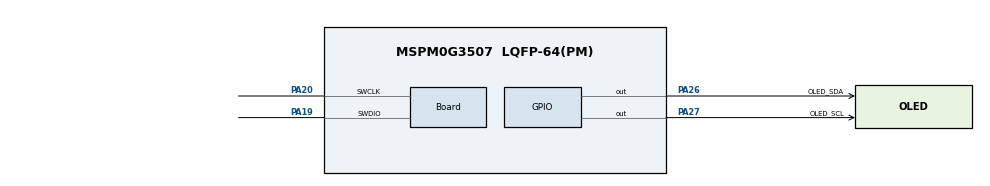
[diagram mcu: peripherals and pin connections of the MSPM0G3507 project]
/**
 * LP-MSPM0G3507 eight-channel line sensor test configuration.
 * I2C1: SCL=PA15, SDA=PA16. OLED software I2C: SCL=PA27, SDA=PA26.
 * @cliArgs --device "MSPM0G3507" --package "LQFP-64(PM)" --product "mspm0_sdk@2.10.00.04"
 */
const Board         = scripting.addModule("/ti/driverlib/Board");
const GPIO          = scripting.addModule("/ti/driverlib/GPIO", {}, false);
const GPIO1         = GPIO.addInstance();
const I2C           = scripting.addModule("/ti/driverlib/I2C", {}, false);
const I2C1          = I2C.addInstance();
const SYSCTL        = scripting.addModule("/ti/driverlib/SYSCTL");
const ProjectConfig = scripting.addModule("/ti/project_config/ProjectConfig");

Board.peripheral.$assign          = "DEBUGSS";
Board.peripheral.swclkPin.$assign = "PA20";
Board.peripheral.swdioPin.$assign = "PA19";

GPIO1.$name                         = "GPIO_OLED";
GPIO1.port                          = "PORTA";
GPIO1.associatedPins.create(2);
GPIO1.associatedPins[0].$name       = "OLED_SCL";
GPIO1.associatedPins[0].pin.$assign = "PA27";
GPIO1.associatedPins[1].$name       = "OLED_SDA";
GPIO1.associatedPins[1].pin.$assign = "PA26";

I2C1.$name                             = "I2C_1";
I2C1.basicEnableController             = true;
I2C1.basicControllerStandardBusSpeed   = "Fast";
I2C1.peripheral.$assign                = "I2C1";
I2C1.sdaPinConfig.hideOutputInversion  = scripting.forceWrite(false);
I2C1.sdaPinConfig.onlyInternalResistor = scripting.forceWrite(false);
I2C1.sdaPinConfig.passedPeripheralType = scripting.forceWrite("Digital");
I2C1.sdaPinConfig.$name                = "ti_driverlib_gpio_GPIOPinGeneric0";
I2C1.sclPinConfig.hideOutputInversion  = scripting.forceWrite(false);
I2C1.sclPinConfig.onlyInternalResistor = scripting.forceWrite(false);
I2C1.sclPinConfig.passedPeripheralType = scripting.forceWrite("Digital");
I2C1.sclPinConfig.$name                = "ti_driverlib_gpio_GPIOPinGeneric1";

SYSCTL.clockTreeEn = true;

ProjectConfig.deviceSpin = "MSPM0G3507";

I2C1.peripheral.sdaPin.$suggestSolution = "PA16";
I2C1.peripheral.sclPin.$suggestSolution = "PA15";
